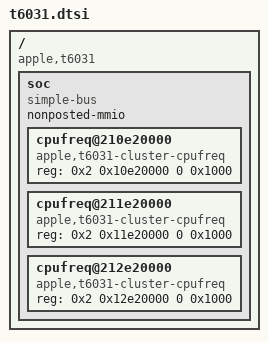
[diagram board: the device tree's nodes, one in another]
// SPDX-License-Identifier: GPL-2.0+ OR MIT
/*
 * Apple T6031 "M3 Max" SoC
 *
 * Copyright The Asahi Linux Contributors
 */

#include <dt-bindings/interrupt-controller/apple-aic.h>
#include <dt-bindings/interrupt-controller/irq.h>

#include "multi-die-cpp.h"

#include "t603x-common.dtsi"

/ {

	compatible = "apple,t6031", "apple,arm-platform";

	soc: soc {
		compatible = "simple-bus";
		#address-cells = <2>;
		#size-cells = <2>;
		nonposted-mmio;

		ranges;
		// filled via templates at the end of the file
	
	DIE_NODE(cpufreq_e): cpufreq@210e20000 {
		compatible = "apple,t6031-cluster-cpufreq", "apple,t8112-cluster-cpufreq";
		reg = <0x2 0x10e20000 0 0x1000>;
		#performance-domain-cells = <0>;
	};

	DIE_NODE(cpufreq_p0): cpufreq@211e20000 {
		compatible = "apple,t6031-cluster-cpufreq", "apple,t8112-cluster-cpufreq";
		reg = <0x2 0x11e20000 0 0x1000>;
		#performance-domain-cells = <0>;
	};

	DIE_NODE(cpufreq_p1): cpufreq@212e20000 {
		compatible = "apple,t6031-cluster-cpufreq", "apple,t8112-cluster-cpufreq";
		reg = <0x2 0x12e20000 0 0x1000>;
		#performance-domain-cells = <0>;
	};
};
};

#define DIE
#define DIE_NO 0

&{/soc} {
	#include "t603x-die0.dtsi"
	#include "t603x-dieX.dtsi"
	//#include "t602x-nvme.dtsi"
};

#include "t603x-gpio-pins.dtsi"
#include "t6031-pmgr.dtsi"

#undef DIE
#undef DIE_NO


// aic_affinities

// gpu compatible here
